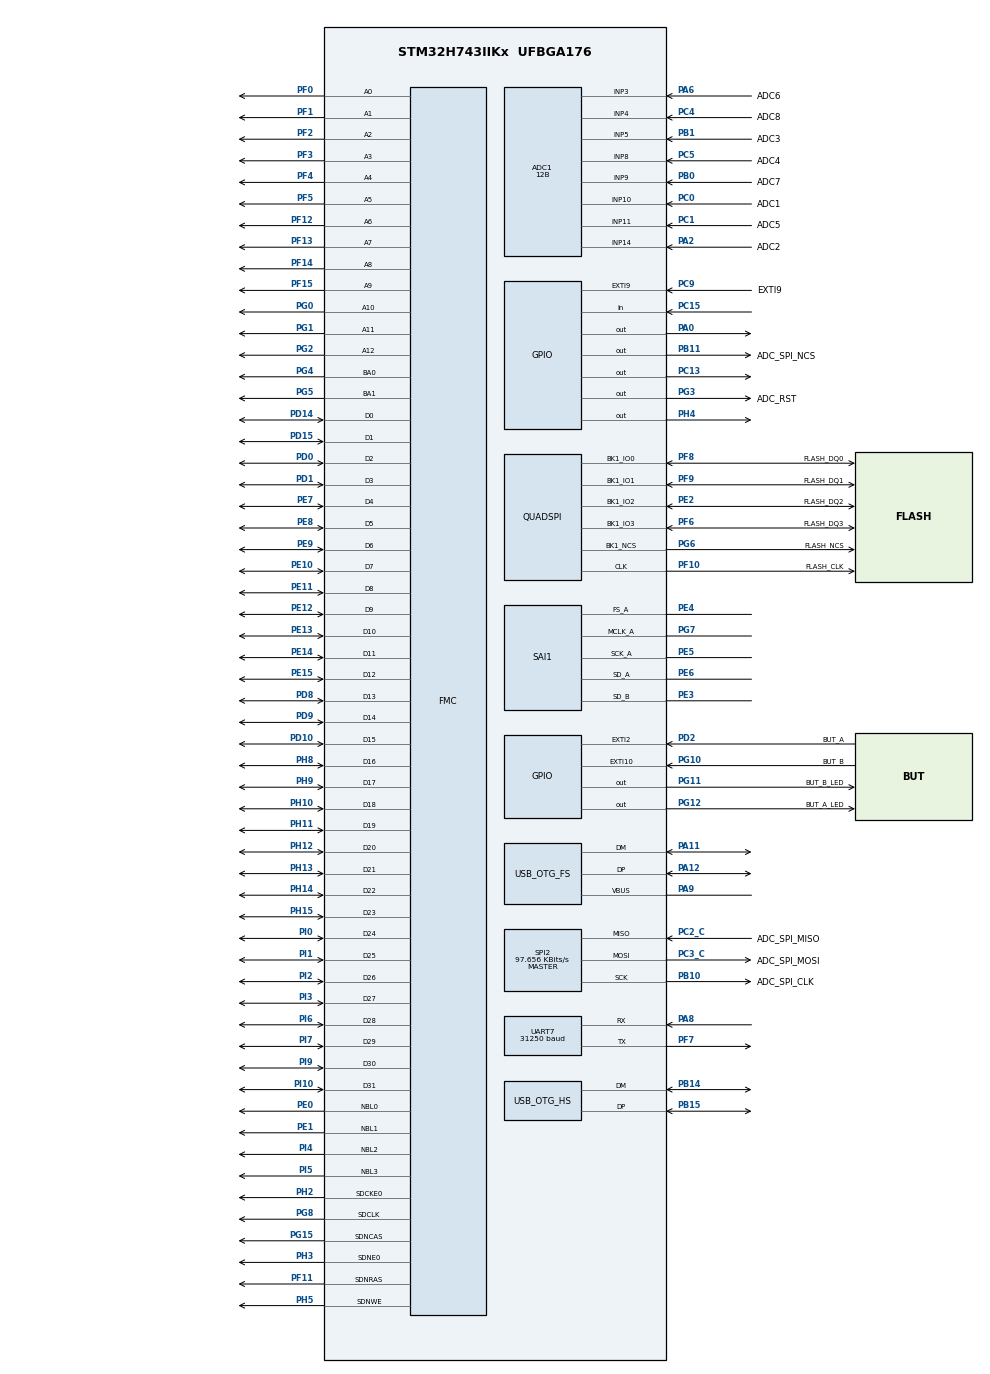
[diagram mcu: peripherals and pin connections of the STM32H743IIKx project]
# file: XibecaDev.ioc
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ADC1.Channel-0\#ChannelRegularConversion=ADC_CHANNEL_10
ADC1.Channel-1\#ChannelRegularConversion=ADC_CHANNEL_11
ADC1.Channel-2\#ChannelRegularConversion=ADC_CHANNEL_14
ADC1.Channel-3\#ChannelRegularConversion=ADC_CHANNEL_3
ADC1.Channel-4\#ChannelRegularConversion=ADC_CHANNEL_5
ADC1.Channel-5\#ChannelRegularConversion=ADC_CHANNEL_9
ADC1.Channel-6\#ChannelRegularConversion=ADC_CHANNEL_8
ADC1.Channel-7\#ChannelRegularConversion=ADC_CHANNEL_4
ADC1.ClockPrescaler=ADC_CLOCK_ASYNC_DIV128
ADC1.ContinuousConvMode=ENABLE
ADC1.ConversionDataManagement=ADC_CONVERSIONDATA_DMA_CIRCULAR
ADC1.EOCSelection=ADC_EOC_SEQ_CONV
ADC1.NbrOfConversion=8
ADC1.NbrOfConversionFlag=1
ADC1.OffsetNumber-0\#ChannelRegularConversion=ADC_OFFSET_NONE
ADC1.OffsetNumber-1\#ChannelRegularConversion=ADC_OFFSET_NONE
ADC1.OffsetNumber-2\#ChannelRegularConversion=ADC_OFFSET_NONE
ADC1.OffsetNumber-3\#ChannelRegularConversion=ADC_OFFSET_NONE
ADC1.OffsetNumber-4\#ChannelRegularConversion=ADC_OFFSET_NONE
ADC1.OffsetNumber-5\#ChannelRegularConversion=ADC_OFFSET_NONE
ADC1.OffsetNumber-6\#ChannelRegularConversion=ADC_OFFSET_NONE
ADC1.OffsetNumber-7\#ChannelRegularConversion=ADC_OFFSET_NONE
ADC1.OffsetSignedSaturation-0\#ChannelRegularConversion=DISABLE
ADC1.OffsetSignedSaturation-1\#ChannelRegularConversion=DISABLE
ADC1.OffsetSignedSaturation-2\#ChannelRegularConversion=DISABLE
ADC1.OffsetSignedSaturation-3\#ChannelRegularConversion=DISABLE
ADC1.Overrun=ADC_OVR_DATA_OVERWRITTEN
ADC1.OversamplingMode=DISABLE
ADC1.Rank-0\#ChannelRegularConversion=1
ADC1.Rank-1\#ChannelRegularConversion=2
ADC1.Rank-2\#ChannelRegularConversion=3
ADC1.Rank-3\#ChannelRegularConversion=4
ADC1.Rank-4\#ChannelRegularConversion=5
ADC1.Rank-5\#ChannelRegularConversion=6
ADC1.Rank-6\#ChannelRegularConversion=7
ADC1.Rank-7\#ChannelRegularConversion=8
ADC1.Resolution=ADC_RESOLUTION_12B
ADC1.SamplingTime-0\#ChannelRegularConversion=ADC_SAMPLETIME_64CYCLES_5
ADC1.SamplingTime-1\#ChannelRegularConversion=ADC_SAMPLETIME_64CYCLES_5
ADC1.SamplingTime-2\#ChannelRegularConversion=ADC_SAMPLETIME_64CYCLES_5
ADC1.SamplingTime-3\#ChannelRegularConversion=ADC_SAMPLETIME_64CYCLES_5
ADC1.SamplingTime-4\#ChannelRegularConversion=ADC_SAMPLETIME_64CYCLES_5
ADC1.SamplingTime-5\#ChannelRegularConversion=ADC_SAMPLETIME_64CYCLES_5
ADC1.SamplingTime-6\#ChannelRegularConversion=ADC_SAMPLETIME_64CYCLES_5
ADC1.SamplingTime-7\#ChannelRegularConversion=ADC_SAMPLETIME_64CYCLES_5
ADC1.master=1
Dma.ADC1.2.Direction=DMA_PERIPH_TO_MEMORY
Dma.ADC1.2.EventEnable=DISABLE
Dma.ADC1.2.FIFOMode=DMA_FIFOMODE_DISABLE
Dma.ADC1.2.Instance=DMA1_Stream3
Dma.ADC1.2.MemDataAlignment=DMA_MDATAALIGN_HALFWORD
Dma.ADC1.2.MemInc=DMA_MINC_ENABLE
Dma.ADC1.2.Mode=DMA_CIRCULAR
Dma.ADC1.2.PeriphDataAlignment=DMA_PDATAALIGN_HALFWORD
Dma.ADC1.2.PeriphInc=DMA_PINC_DISABLE
Dma.ADC1.2.Polarity=HAL_DMAMUX_REQ_GEN_RISING
Dma.ADC1.2.Priority=DMA_PRIORITY_LOW
Dma.ADC1.2.RequestNumber=1
Dma.ADC1.2.SignalID=NONE
Dma.ADC1.2.SyncEnable=DISABLE
Dma.ADC1.2.SyncPolarity=HAL_DMAMUX_SYNC_NO_EVENT
Dma.ADC1.2.SyncRequestNumber=1
Dma.ADC1.2.SyncSignalID=NONE
Dma.Request0=SAI1_A
Dma.Request1=SAI1_B
Dma.Request2=ADC1
Dma.Request3=UART7_RX
Dma.Request4=UART7_TX
Dma.SAI1_A.0.Direction=DMA_PERIPH_TO_MEMORY
Dma.SAI1_A.0.EventEnable=DISABLE
Dma.SAI1_A.0.FIFOMode=DMA_FIFOMODE_DISABLE
Dma.SAI1_A.0.Instance=DMA1_Stream0
Dma.SAI1_A.0.MemDataAlignment=DMA_MDATAALIGN_WORD
Dma.SAI1_A.0.MemInc=DMA_MINC_ENABLE
Dma.SAI1_A.0.Mode=DMA_CIRCULAR
Dma.SAI1_A.0.PeriphDataAlignment=DMA_PDATAALIGN_WORD
Dma.SAI1_A.0.PeriphInc=DMA_PINC_DISABLE
Dma.SAI1_A.0.Polarity=HAL_DMAMUX_REQ_GEN_RISING
Dma.SAI1_A.0.Priority=DMA_PRIORITY_VERY_HIGH
Dma.SAI1_A.0.RequestNumber=1
Dma.SAI1_A.0.SignalID=NONE
Dma.SAI1_A.0.SyncEnable=DISABLE
Dma.SAI1_A.0.SyncPolarity=HAL_DMAMUX_SYNC_NO_EVENT
Dma.SAI1_A.0.SyncRequestNumber=1
Dma.SAI1_A.0.SyncSignalID=NONE
Dma.SAI1_B.1.Direction=DMA_MEMORY_TO_PERIPH
Dma.SAI1_B.1.EventEnable=DISABLE
Dma.SAI1_B.1.FIFOMode=DMA_FIFOMODE_DISABLE
Dma.SAI1_B.1.Instance=DMA1_Stream1
Dma.SAI1_B.1.MemDataAlignment=DMA_MDATAALIGN_WORD
Dma.SAI1_B.1.MemInc=DMA_MINC_ENABLE
Dma.SAI1_B.1.Mode=DMA_CIRCULAR
Dma.SAI1_B.1.PeriphDataAlignment=DMA_PDATAALIGN_WORD
Dma.SAI1_B.1.PeriphInc=DMA_PINC_DISABLE
Dma.SAI1_B.1.Polarity=HAL_DMAMUX_REQ_GEN_RISING
Dma.SAI1_B.1.Priority=DMA_PRIORITY_VERY_HIGH
Dma.SAI1_B.1.RequestNumber=1
Dma.SAI1_B.1.SignalID=NONE
Dma.SAI1_B.1.SyncEnable=DISABLE
Dma.SAI1_B.1.SyncPolarity=HAL_DMAMUX_SYNC_NO_EVENT
Dma.SAI1_B.1.SyncRequestNumber=1
Dma.SAI1_B.1.SyncSignalID=NONE
Dma.UART7_RX.3.Direction=DMA_PERIPH_TO_MEMORY
Dma.UART7_RX.3.EventEnable=DISABLE
Dma.UART7_RX.3.FIFOMode=DMA_FIFOMODE_DISABLE
Dma.UART7_RX.3.Instance=DMA1_Stream2
Dma.UART7_RX.3.MemDataAlignment=DMA_MDATAALIGN_BYTE
Dma.UART7_RX.3.MemInc=DMA_MINC_ENABLE
Dma.UART7_RX.3.Mode=DMA_NORMAL
Dma.UART7_RX.3.PeriphDataAlignment=DMA_PDATAALIGN_BYTE
Dma.UART7_RX.3.PeriphInc=DMA_PINC_DISABLE
Dma.UART7_RX.3.Polarity=HAL_DMAMUX_REQ_GEN_RISING
Dma.UART7_RX.3.Priority=DMA_PRIORITY_LOW
Dma.UART7_RX.3.RequestNumber=1
Dma.UART7_RX.3.SignalID=NONE
Dma.UART7_RX.3.SyncEnable=DISABLE
Dma.UART7_RX.3.SyncPolarity=HAL_DMAMUX_SYNC_NO_EVENT
Dma.UART7_RX.3.SyncRequestNumber=1
Dma.UART7_RX.3.SyncSignalID=NONE
Dma.UART7_TX.4.Direction=DMA_MEMORY_TO_PERIPH
Dma.UART7_TX.4.EventEnable=DISABLE
Dma.UART7_TX.4.FIFOMode=DMA_FIFOMODE_DISABLE
Dma.UART7_TX.4.Instance=DMA1_Stream4
Dma.UART7_TX.4.MemDataAlignment=DMA_MDATAALIGN_BYTE
Dma.UART7_TX.4.MemInc=DMA_MINC_ENABLE
Dma.UART7_TX.4.Mode=DMA_NORMAL
Dma.UART7_TX.4.PeriphDataAlignment=DMA_PDATAALIGN_BYTE
Dma.UART7_TX.4.PeriphInc=DMA_PINC_DISABLE
Dma.UART7_TX.4.Polarity=HAL_DMAMUX_REQ_GEN_RISING
Dma.UART7_TX.4.Priority=DMA_PRIORITY_LOW
Dma.UART7_TX.4.RequestNumber=1
Dma.UART7_TX.4.SignalID=NONE
Dma.UART7_TX.4.SyncEnable=DISABLE
Dma.UART7_TX.4.SyncPolarity=HAL_DMAMUX_SYNC_NO_EVENT
Dma.UART7_TX.4.SyncRequestNumber=1
Dma.UART7_TX.4.SyncSignalID=NONE
FMC.CASLatency1=FMC_SDRAM_CAS_LATENCY_3
FMC.ColumnBitsNumber1=FMC_SDRAM_COLUMN_BITS_NUM_9
FMC.ExitSelfRefreshDelay1=7
FMC.LoadToActiveDelay1=2
FMC.RCDDelay1=10
FMC.RPDelay1=1
FMC.RPDelay2=1
FMC.ReadBurst1=FMC_SDRAM_RBURST_ENABLE
FMC.ReadBurst2=FMC_SDRAM_RBURST_ENABLE
FMC.RowCycleDelay1=8
FMC.RowCycleDelay2=8
FMC.SDClockPeriod1=FMC_SDRAM_CLOCK_PERIOD_2
FMC.SDClockPeriod2=FMC_SDRAM_CLOCK_PERIOD_2
FMC.SelfRefreshTime1=4
FMC.WriteRecoveryTime1=3
FREERTOS.INCLUDE_vTaskDelayUntil=1
FREERTOS.Tasks01=defaultTask,0,1024,StartDefaultTask,Default,NULL,Dynamic,NULL,NULL
FREERTOS.configCHECK_FOR_STACK_OVERFLOW=2
FREERTOS.configUSE_IDLE_HOOK=0
FREERTOS.configUSE_MALLOC_FAILED_HOOK=1
FREERTOS.configUSE_MUTEXES=0
FREERTOS.configUSE_PREEMPTION=0
FREERTOS.configUSE_TICK_HOOK=0
Mcu.Family=STM32H7
Mcu.Name=STM32H743IIKx
Mcu.Package=UFBGA176
NVIC.ADC_IRQn=true\:5\:0\:false\:false\:true\:true\:true\:true
NVIC.DMA1_Stream0_IRQn=true\:5\:0\:false\:false\:true\:true\:false\:true
NVIC.DMA1_Stream1_IRQn=true\:5\:0\:false\:false\:true\:true\:false\:true
NVIC.DMA1_Stream2_IRQn=true\:5\:0\:false\:false\:true\:true\:false\:true
NVIC.DMA1_Stream3_IRQn=true\:5\:0\:false\:false\:true\:true\:false\:true
NVIC.DMA1_Stream4_IRQn=true\:5\:0\:false\:false\:true\:true\:false\:true
NVIC.EXTI15_10_IRQn=true\:5\:0\:false\:false\:true\:true\:true\:true
NVIC.EXTI2_IRQn=true\:5\:0\:false\:false\:true\:true\:true\:true
NVIC.OTG_FS_IRQn=true\:5\:0\:false\:false\:true\:true\:true\:true
NVIC.OTG_HS_IRQn=true\:5\:0\:false\:false\:true\:true\:false\:true
NVIC.PriorityGroup=NVIC_PRIORITYGROUP_4
NVIC.QUADSPI_IRQn=true\:5\:0\:false\:false\:true\:true\:true\:true
NVIC.SAI1_IRQn=true\:5\:0\:false\:false\:true\:true\:true\:true
NVIC.UART7_IRQn=true\:5\:0\:false\:false\:true\:true\:true\:true
PA0.Signal=GPIO_Output
PA11.Mode=Device_Only
PA11.Signal=USB_OTG_FS_DM
PA12.Mode=Device_Only
PA12.Signal=USB_OTG_FS_DP
PA13\ (JTMS/SWDIO).Mode=Trace_Asynchronous_SW
PA13\ (JTMS/SWDIO).Signal=DEBUG_JTMS-SWDIO
PA14\ (JTCK/SWCLK).Mode=Trace_Asynchronous_SW
PA14\ (JTCK/SWCLK).Signal=DEBUG_JTCK-SWCLK
PA2.GPIO_Label=ADC2
PA2.Signal=ADCx_INP14
PA6.GPIO_Label=ADC6
PA6.Signal=ADCx_INP3
PA8.Mode=Asynchronous
PA8.Signal=UART7_RX
PA9.Mode=Activate_VBUS
PA9.Signal=USB_OTG_FS_VBUS
PB0.GPIO_Label=ADC7
PB0.Signal=ADCx_INP9
PB1.GPIO_Label=ADC3
PB1.Signal=ADCx_INP5
PB10.GPIO_Label=ADC_SPI_CLK
PB10.GPIO_Speed=GPIO_SPEED_FREQ_VERY_HIGH
PB10.Mode=Full_Duplex_Master
PB10.Signal=SPI2_SCK
PB11.GPIO_Label=ADC_SPI_NCS
PB11.Signal=GPIO_Output
PB14.Mode=Host_FS
PB14.Signal=USB_OTG_HS_DM
PB15.Mode=Host_FS
PB15.Signal=USB_OTG_HS_DP
PB3\ (JTDO/TRACESWO).Mode=Trace_Asynchronous_SW
PB3\ (JTDO/TRACESWO).Signal=DEBUG_JTDO-SWO
PB7.Signal=I2C1_SDA
PC0.GPIO_Label=ADC1
PC0.Signal=ADCx_INP10
PC1.GPIO_Label=ADC5
PC1.Signal=ADCx_INP11
PC10.GPIO_Speed=GPIO_SPEED_FREQ_HIGH
PC10.Signal=SharedStack_PC10
PC10.Stacked=true
PC12.GPIO_Speed=GPIO_SPEED_FREQ_HIGH
PC12.Signal=SharedStack_PC12
PC12.Stacked=true
PC13.Signal=GPIO_Output
PC15-OSC32_OUT\ (OSC32_OUT).Signal=GPIO_Input
PC2_C.GPIO_Label=ADC_SPI_MISO
PC2_C.GPIO_Speed=GPIO_SPEED_FREQ_VERY_HIGH
PC2_C.Mode=Full_Duplex_Master
PC2_C.Signal=SPI2_MISO
PC3_C.GPIO_Label=ADC_SPI_MOSI
PC3_C.GPIO_Speed=GPIO_SPEED_FREQ_VERY_HIGH
PC3_C.Mode=Full_Duplex_Master
PC3_C.Signal=SPI2_MOSI
PC4.GPIO_Label=ADC8
PC4.Signal=ADCx_INP4
PC5.GPIO_Label=ADC4
PC5.Signal=ADCx_INP8
PC9.GPIO_Label=EXTI9
PC9.Signal=SharedStack_PC9
PC9.Stacked=true
PD0.Signal=FMC_D2_DA2
PD1.Signal=FMC_D3_DA3
PD10.Signal=FMC_D15_DA15
PD14.Signal=FMC_D0_DA0
PD15.Signal=FMC_D1_DA1
PD2.GPIO_Label=BUT_A
PD2.GPIO_PuPd=GPIO_PULLUP
PD2.Signal=GPXTI2
PD8.Signal=FMC_D13_DA13
PD9.Signal=FMC_D14_DA14
PE0.Signal=FMC_NBL0
PE1.Signal=FMC_NBL1
PE10.Signal=FMC_D7_DA7
PE11.Signal=FMC_D8_DA8
PE12.Signal=FMC_D9_DA9
PE13.Signal=FMC_D10_DA10
PE14.Signal=FMC_D11_DA11
PE15.Signal=FMC_D12_DA12
PE2.GPIO_Label=FLASH_DQ2
PE2.GPIO_Speed=GPIO_SPEED_FREQ_VERY_HIGH
PE2.Mode=Single Bank 1
PE2.Signal=QUADSPI_BK1_IO2
PE3.GPIO_Speed=GPIO_SPEED_FREQ_VERY_HIGH
PE3.Mode=SAI_B_SyncSlave
PE3.Signal=SAI1_SD_B
PE4.GPIO_Speed=GPIO_SPEED_FREQ_VERY_HIGH
PE4.Mode=SAI_A_MasterWithClock
PE4.Signal=SAI1_FS_A
PE5.GPIO_Speed=GPIO_SPEED_FREQ_VERY_HIGH
PE5.Mode=SAI_A_MasterWithClock
PE5.Signal=SAI1_SCK_A
PE6.GPIO_Speed=GPIO_SPEED_FREQ_VERY_HIGH
PE6.Mode=SAI_A_MasterWithClock
PE6.Signal=SAI1_SD_A
PE7.Signal=FMC_D4_DA4
PE8.Signal=FMC_D5_DA5
PE9.Signal=FMC_D6_DA6
PF0.Signal=FMC_A0
PF1.Signal=FMC_A1
PF10.GPIO_Label=FLASH_CLK
PF10.GPIO_Speed=GPIO_SPEED_FREQ_VERY_HIGH
PF10.Mode=Single Bank 1
PF10.Signal=QUADSPI_CLK
PF11.Signal=FMC_SDNRAS
PF12.Signal=FMC_A6
PF13.Signal=FMC_A7
PF14.Signal=FMC_A8
PF15.Signal=FMC_A9
PF2.Signal=FMC_A2
PF3.Signal=FMC_A3
PF4.Signal=FMC_A4
PF5.Signal=FMC_A5
PF6.GPIO_Label=FLASH_DQ3
PF6.GPIO_Speed=GPIO_SPEED_FREQ_VERY_HIGH
PF6.Mode=Single Bank 1
PF6.Signal=QUADSPI_BK1_IO3
PF7.Mode=Asynchronous
PF7.Signal=UART7_TX
PF8.GPIO_Label=FLASH_DQ0
PF8.GPIO_Speed=GPIO_SPEED_FREQ_VERY_HIGH
PF8.Mode=Single Bank 1
PF8.Signal=QUADSPI_BK1_IO0
PF9.GPIO_Label=FLASH_DQ1
PF9.GPIO_Speed=GPIO_SPEED_FREQ_VERY_HIGH
PF9.Mode=Single Bank 1
PF9.Signal=QUADSPI_BK1_IO1
PG0.Signal=FMC_A10
PG1.Signal=FMC_A11
PG10.GPIO_Label=BUT_B
PG10.GPIO_PuPd=GPIO_PULLUP
PG10.Signal=GPXTI10
PG11.GPIO_Label=BUT_B_LED
PG11.Signal=GPIO_Output
PG12.GPIO_Label=BUT_A_LED
PG12.Signal=GPIO_Output
PG15.Signal=FMC_SDNCAS
PG2.Signal=FMC_A12
PG3.GPIO_Label=ADC_RST
PG3.Signal=GPIO_Output
PG4.Signal=FMC_A14_BA0
PG5.Signal=FMC_A15_BA1
PG6.GPIO_Label=FLASH_NCS
PG6.GPIO_Speed=GPIO_SPEED_FREQ_VERY_HIGH
PG6.Mode=Single Bank 1
PG6.Signal=QUADSPI_BK1_NCS
PG7.GPIO_Speed=GPIO_SPEED_FREQ_VERY_HIGH
PG7.Mode=SAI_A_MasterWithClock
PG7.Signal=SAI1_MCLK_A
PG8.Signal=FMC_SDCLK
PH0-OSC_IN\ (PH0).Mode=HSE-External-Oscillator
PH0-OSC_IN\ (PH0).Signal=RCC_OSC_IN
PH1-OSC_OUT\ (PH1).Mode=HSE-External-Oscillator
PH1-OSC_OUT\ (PH1).Signal=RCC_OSC_OUT
PH10.Signal=FMC_D18
PH11.Signal=FMC_D19
PH12.Signal=FMC_D20
PH13.Signal=FMC_D21
PH14.Signal=FMC_D22
PH15.Signal=FMC_D23
PH2.Mode=SdramChipSelect1_1
PH2.Signal=FMC_SDCKE0
PH3.Mode=SdramChipSelect1_1
PH3.Signal=FMC_SDNE0
PH4.Signal=GPIO_Output
PH5.Signal=FMC_SDNWE
PH8.Signal=FMC_D16
PH9.Signal=FMC_D17
PI0.Signal=FMC_D24
PI1.Signal=FMC_D25
PI10.Signal=FMC_D31
PI2.Signal=FMC_D26
PI3.Signal=FMC_D27
PI4.Signal=FMC_NBL2
PI5.Signal=FMC_NBL3
PI6.Signal=FMC_D28
PI7.Signal=FMC_D29
PI9.Signal=FMC_D30
ProjectManager.HeapSize=0x200
ProjectManager.StackSize=0x400
ProjectManager.TargetToolchain=Other Toolchains (GPDSC)
QUADSPI.ClockPrescaler=9
QUADSPI.FifoThreshold=4
QUADSPI.FlashSize=22
RCC.ADCFreq_Value=25000000
RCC.APB1Freq_Value=120000000
RCC.APB2Freq_Value=120000000
RCC.APB3Freq_Value=120000000
RCC.APB4Freq_Value=120000000
RCC.CortexFreq_Value=480000000
RCC.D1PPRE=RCC_APB3_DIV2
RCC.D2PPRE1=RCC_APB1_DIV2
RCC.D2PPRE2=RCC_APB2_DIV2
RCC.D3PPRE=RCC_APB4_DIV2
RCC.DIVM1=1
RCC.DIVM2=1
RCC.DIVM3=7
RCC.DIVN1=120
RCC.DIVN2=18
RCC.DIVN3=172
RCC.DIVP2=6
RCC.DIVQ1=5
RCC.HCLKFreq_Value=240000000
RCC.HPRE=RCC_HCLK_DIV2
RCC.HSE_VALUE=8000000
RCC.PLL2FRACN=6144
RCC.PLL3FRACN=0
RCC.PLLFRACN=0
RCC.PLLSourceVirtual=RCC_PLLSOURCE_HSE
RCC.PWR_Regulator_Voltage_Scale=PWR_REGULATOR_VOLTAGE_SCALE0
RCC.SAI1CLockSelection=RCC_SAI1CLKSOURCE_PLL3
RCC.SPI123CLockSelection=RCC_SPI123CLKSOURCE_PLL2
RCC.SYSCLKFreq_VALUE=480000000
RCC.SYSCLKSource=RCC_SYSCLKSOURCE_PLLCLK
RCC.USBCLockSelection=RCC_USBCLKSOURCE_HSI48
RCC.USBFreq_Value=48000000
SAI1.ActiveFrameLength-SAI_A_MasterWithClock=128
SAI1.ActiveFrameLength-SAI_B_SyncSlave=128
SAI1.AudioFrequency-SAI_A_MasterWithClock=SAI_AUDIO_FREQUENCY_48K
SAI1.AudioMode-SAI_A_MasterWithClock=SAI_MODEMASTER_RX
SAI1.AudioMode-SAI_B_SyncSlave=SAI_MODESLAVE_TX
SAI1.ClockStrobing-SAI_A_MasterWithClock=SAI_CLOCKSTROBING_RISINGEDGE
SAI1.DataSize-SAI_A_MasterWithClock=SAI_DATASIZE_24
SAI1.DataSize-SAI_B_SyncSlave=SAI_DATASIZE_24
SAI1.ErrorAudioFreq-SAI_A_MasterWithClock=-0.01 %
SAI1.FSDefinition-SAI_A_MasterWithClock=SAI_FS_CHANNEL_IDENTIFICATION
SAI1.FSDefinition-SAI_B_SyncSlave=SAI_FS_CHANNEL_IDENTIFICATION
SAI1.FSOffset-SAI_A_MasterWithClock=SAI_FS_BEFOREFIRSTBIT
SAI1.FSOffset-SAI_B_SyncSlave=SAI_FS_BEFOREFIRSTBIT
SAI1.FSPolarity-SAI_A_MasterWithClock=SAI_FS_ACTIVE_HIGH
SAI1.FSPolarity-SAI_B_SyncSlave=SAI_FS_ACTIVE_HIGH
SAI1.FrameLength-SAI_A_MasterWithClock=256
SAI1.FrameLength-SAI_B_SyncSlave=256
SAI1.Instance-SAI_A_MasterWithClock=SAI$Index_Block_A
SAI1.Instance-SAI_B_SyncSlave=SAI$Index_Block_B
SAI1.MClockEnable-SAI_A_MasterWithClock=SAI_MASTERCLOCK_ENABLE
SAI1.NoDivider-SAI_A_MasterWithClock=SAI_MASTERDIVIDER_ENABLE
SAI1.OutputDrive-SAI_A_MasterWithClock=SAI_OUTPUTDRIVE_ENABLE
SAI1.OutputDrive-SAI_B_SyncSlave=SAI_OUTPUTDRIVE_ENABLE
SAI1.RealAudioFreq-SAI_A_MasterWithClock=47.991 KHz
SAI1.SlotActive-SAI_A_MasterWithClock=0x0000FFFF
SAI1.SlotActive-SAI_B_SyncSlave=0x0000FFFF
SAI1.SlotNumber-SAI_A_MasterWithClock=8
SAI1.SlotNumber-SAI_B_SyncSlave=8
SAI1.SlotSize-SAI_A_MasterWithClock=SAI_SLOTSIZE_32B
SAI1.SlotSize-SAI_B_SyncSlave=SAI_SLOTSIZE_32B
SAI1.VirtualMode-SAI_A_MasterWithClock=VM_MASTER
SAI1.VirtualMode-SAI_B_SyncSlave=VM_SLAVE
SAI1.VirtualSlotActive-SAI_A_MasterWithClock=SAI_SLOTACTIVE_ALL
SAI1.VirtualSlotActive-SAI_B_SyncSlave=SAI_SLOTACTIVE_ALL
SH.ADCx_INP10.0=ADC1_INP10,IN10-Single-Ended
SH.ADCx_INP11.0=ADC1_INP11,IN11-Single-Ended
SH.ADCx_INP14.0=ADC1_INP14,IN14-Single-Ended
SH.ADCx_INP3.0=ADC1_INP3,IN3-Single-Ended
SH.ADCx_INP4.0=ADC1_INP4,IN4-Single-Ended
SH.ADCx_INP5.0=ADC1_INP5,IN5-Single-Ended
SH.ADCx_INP8.0=ADC1_INP8,IN8-Single-Ended
SH.ADCx_INP9.0=ADC1_INP9,IN9-Single-Ended
SH.FMC_A0.0=FMC_A0,13b-sda1
SH.FMC_A1.0=FMC_A1,13b-sda1
SH.FMC_A10.0=FMC_A10,13b-sda1
SH.FMC_A11.0=FMC_A11,13b-sda1
SH.FMC_A12.0=FMC_A12,13b-sda1
SH.FMC_A14_BA0.0=FMC_BA0,FourSdramBanks1
SH.FMC_A15_BA1.0=FMC_BA1,FourSdramBanks1
SH.FMC_A2.0=FMC_A2,13b-sda1
SH.FMC_A3.0=FMC_A3,13b-sda1
SH.FMC_A4.0=FMC_A4,13b-sda1
SH.FMC_A5.0=FMC_A5,13b-sda1
SH.FMC_A6.0=FMC_A6,13b-sda1
SH.FMC_A7.0=FMC_A7,13b-sda1
SH.FMC_A8.0=FMC_A8,13b-sda1
SH.FMC_A9.0=FMC_A9,13b-sda1
SH.FMC_D0_DA0.0=FMC_D0,sd-32b-d1
SH.FMC_D10_DA10.0=FMC_D10,sd-32b-d1
SH.FMC_D11_DA11.0=FMC_D11,sd-32b-d1
SH.FMC_D12_DA12.0=FMC_D12,sd-32b-d1
SH.FMC_D13_DA13.0=FMC_D13,sd-32b-d1
SH.FMC_D14_DA14.0=FMC_D14,sd-32b-d1
SH.FMC_D15_DA15.0=FMC_D15,sd-32b-d1
SH.FMC_D16.0=FMC_D16,sd-32b-d1
SH.FMC_D17.0=FMC_D17,sd-32b-d1
SH.FMC_D18.0=FMC_D18,sd-32b-d1
SH.FMC_D19.0=FMC_D19,sd-32b-d1
SH.FMC_D1_DA1.0=FMC_D1,sd-32b-d1
SH.FMC_D20.0=FMC_D20,sd-32b-d1
SH.FMC_D21.0=FMC_D21,sd-32b-d1
SH.FMC_D22.0=FMC_D22,sd-32b-d1
SH.FMC_D23.0=FMC_D23,sd-32b-d1
SH.FMC_D24.0=FMC_D24,sd-32b-d1
SH.FMC_D25.0=FMC_D25,sd-32b-d1
SH.FMC_D26.0=FMC_D26,sd-32b-d1
SH.FMC_D27.0=FMC_D27,sd-32b-d1
SH.FMC_D28.0=FMC_D28,sd-32b-d1
SH.FMC_D29.0=FMC_D29,sd-32b-d1
SH.FMC_D2_DA2.0=FMC_D2,sd-32b-d1
SH.FMC_D30.0=FMC_D30,sd-32b-d1
SH.FMC_D31.0=FMC_D31,sd-32b-d1
SH.FMC_D3_DA3.0=FMC_D3,sd-32b-d1
SH.FMC_D4_DA4.0=FMC_D4,sd-32b-d1
SH.FMC_D5_DA5.0=FMC_D5,sd-32b-d1
SH.FMC_D6_DA6.0=FMC_D6,sd-32b-d1
SH.FMC_D7_DA7.0=FMC_D7,sd-32b-d1
SH.FMC_D8_DA8.0=FMC_D8,sd-32b-d1
SH.FMC_D9_DA9.0=FMC_D9,sd-32b-d1
SH.FMC_NBL0.0=FMC_NBL0,Sd4ByteEnable1
SH.FMC_NBL1.0=FMC_NBL1,Sd4ByteEnable1
SH.FMC_NBL2.0=FMC_NBL2,Sd4ByteEnable1
SH.FMC_NBL3.0=FMC_NBL3,Sd4ByteEnable1
SH.FMC_SDCLK.0=FMC_SDCLK,13b-sda1
SH.FMC_SDNCAS.0=FMC_SDNCAS,13b-sda1
SH.FMC_SDNRAS.0=FMC_SDNRAS,13b-sda1
SH.FMC_SDNWE.0=FMC_SDNWE,13b-sda1
SH.SharedStack_PC10.0=SDMMC1_D2
SH.SharedStack_PC10.1=SPI3_SCK
SH.SharedStack_PC12.0=SDMMC1_CK
SH.SharedStack_PC12.1=SPI3_MOSI
SH.SharedStack_PC9.0=SDMMC1_D1
SH.SharedStack_PC9.1=TIM3_CH4
SH.SharedStack_PC9.2=TIM8_CH4
SH.SharedStack_PC9.3=GPIO_EXTI9
SPI2.BaudRatePrescaler=SPI_BAUDRATEPRESCALER_256
SPI2.CLKPhase=SPI_PHASE_2EDGE
SPI2.CLKPolarity=SPI_POLARITY_HIGH
SPI2.CalculateBaudRate=97.656 KBits/s
SPI2.DataSize=SPI_DATASIZE_8BIT
SPI2.Direction=SPI_DIRECTION_2LINES
SPI2.Mode=SPI_MODE_MASTER
SPI2.NSSPMode=SPI_NSS_PULSE_DISABLE
SPI2.VirtualType=VM_MASTER
UART7.BaudRate=31250
USB_DEVICE.CLASS_NAME_FS=AUDIO
USB_DEVICE.MANUFACTURER_STRING-AUDIO_FS=Rebel Technology
USB_DEVICE.PID_AUDIO_FS=0xDADA
USB_DEVICE.PRODUCT_STRING_AUDIO_FS=OWL-ACDC
USB_DEVICE.VID-AUDIO_FS=0x1209
USB_DEVICE.VirtualMode-AUDIO_FS=Audio
USB_DEVICE.VirtualModeFS=Audio_FS
USB_HOST.USBH_HandleTypeDef-AUDIO_HS=hUsbHostHS
USB_HOST.USBH_MAX_NUM_CONFIGURATION-AUDIO_HS=5
USB_HOST.USBH_MAX_NUM_SUPPORTED_CLASS-AUDIO_HS=2
USB_HOST.VirtualModeHS=Audio
USB_OTG_FS.VirtualMode=Device_Only
USB_OTG_HS.VirtualMode-Host_FS=Host_FS
VP_FREERTOS_VS_CMSIS_V1.Mode=CMSIS_V1
VP_USB_DEVICE_VS_USB_DEVICE_AUDIO_FS.Mode=AUDIO_FS
VP_USB_HOST_VS_USB_HOST_AUDIO_HS.Mode=AUDIO_HS
board=custom

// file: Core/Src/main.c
/* USER CODE BEGIN Header */
/**
  ******************************************************************************
  * @file           : main.c
  * @brief          : Main program body
  ******************************************************************************
  * @attention
  *
  * <h2><center>&copy; Copyright (c) 2021 STMicroelectronics.
  * All rights reserved.</center></h2>
  *
  * This software component is licensed by ST under Ultimate Liberty license
  * SLA0044, the "License"; You may not use this file except in compliance with
  * the License. You may obtain a copy of the License at:
  *                             www.st.com/SLA0044
  *
  ******************************************************************************
  */
/* USER CODE END Header */
#include "main.h"
#include "cmsis_os.h"
#include "usb_device.h"
#include "usb_host.h"
#include "usb_device.h"
#include "usb_host.h"

/* USER CODE BEGIN Includes */
#include "device.h"
#include "errorhandlers.h"
/* USER CODE END Includes */

ADC_HandleTypeDef hadc1;
DMA_HandleTypeDef hdma_adc1;

QSPI_HandleTypeDef hqspi;

SAI_HandleTypeDef hsai_BlockA1;
SAI_HandleTypeDef hsai_BlockB1;
DMA_HandleTypeDef hdma_sai1_a;
DMA_HandleTypeDef hdma_sai1_b;

SPI_HandleTypeDef hspi2;

UART_HandleTypeDef huart7;
DMA_HandleTypeDef hdma_uart7_rx;
DMA_HandleTypeDef hdma_uart7_tx;

SDRAM_HandleTypeDef hsdram1;

osThreadId defaultTaskHandle;

void SystemClock_Config(void);
void PeriphCommonClock_Config(void);
static void MX_GPIO_Init(void);
static void MX_DMA_Init(void);
static void MX_QUADSPI_Init(void);
static void MX_FMC_Init(void);
static void MX_SAI1_Init(void);
static void MX_ADC1_Init(void);
static void MX_SPI2_Init(void);
static void MX_UART7_Init(void);
void StartDefaultTask(void const * argument);

/* USER CODE BEGIN PFP */
void setup(void);
void loop(void);
void SDRAM_Initialization_Sequence(SDRAM_HandleTypeDef *hsdram);
void initialise_monitor_handles(void);
/* USER CODE END PFP */

int main(void)
{
  /* USER CODE BEGIN 1 */
#ifdef DEBUG
#warning "DEBUG uses printf and semihosting!"
  if(CoreDebug->DHCSR & 0x01)
    initialise_monitor_handles(); // remove when not semi-hosting
  printf("showtime\n");
#endif
#ifdef USE_ICACHE
  /* Enable I-Cache-------------------------------------------------------------*/
  /* After reset, you must invalidate each cache before enabling (SCB_EnableICache) it. */
  SCB_InvalidateICache();
  SCB_EnableICache();
#endif
#ifdef USE_DCACHE
  /* Enable D-Cache-------------------------------------------------------------*/
  /* Before enabling the data cache, you must invalidate the entire data cache (SCB_InvalidateDCache), because external memory might have changed from when the cache was disabled. */
  SCB_InvalidateDCache();
  SCB_EnableDCache();
#endif

  /* Enable D2 domain SRAM Clocks */
  /* presumably done in SystemInit by setting DATA_IN_D2_SRAM ? */
  /* should be started before libc_init_array and LoopCopyData in startup.s */
  /* __HAL_RCC_D2SRAM1_CLK_ENABLE(); */
  /* __HAL_RCC_D2SRAM2_CLK_ENABLE(); */
  /* __HAL_RCC_D2SRAM3_CLK_ENABLE(); */

  /* USER CODE END 1 */

  /* MCU Configuration--------------------------------------------------------*/

  /* Reset of all peripherals, Initializes the Flash interface and the Systick. */
  HAL_Init();

  /* Configure the system clock */
  SystemClock_Config();

/* Configure the peripherals common clocks */
  PeriphCommonClock_Config();

  /* Initialize all configured peripherals */
  MX_GPIO_Init();
  MX_DMA_Init();
  MX_QUADSPI_Init();
  MX_FMC_Init();
  MX_SAI1_Init();
  MX_ADC1_Init();
  MX_SPI2_Init();
  MX_UART7_Init();
  /* USER CODE BEGIN 2 */

#ifdef USE_EXTERNAL_RAM
  SDRAM_Initialization_Sequence(&hsdram1);
#endif

  /* USER CODE END 2 */

  /* Create the thread(s) */
  /* definition and creation of defaultTask */
  osThreadDef(defaultTask, StartDefaultTask, osPriorityNormal, 0, 1024);
  defaultTaskHandle = osThreadCreate(osThread(defaultTask), NULL);

  /* Start scheduler */
  osKernelStart();

  /* We should never get here as control is now taken by the scheduler */
  /* Infinite loop */
  while (1)
  {

  }
}

void SystemClock_Config(void)
{
  RCC_OscInitTypeDef RCC_OscInitStruct = {0};
  RCC_ClkInitTypeDef RCC_ClkInitStruct = {0};

  /** Supply configuration update enable
  */
  HAL_PWREx_ConfigSupply(PWR_LDO_SUPPLY);
  /** Configure the main internal regulator output voltage
  */
  __HAL_PWR_VOLTAGESCALING_CONFIG(PWR_REGULATOR_VOLTAGE_SCALE0);

  while(!__HAL_PWR_GET_FLAG(PWR_FLAG_VOSRDY)) {}
  /** Macro to configure the PLL clock source
  */
  __HAL_RCC_PLL_PLLSOURCE_CONFIG(RCC_PLLSOURCE_HSE);
  /** Initializes the RCC Oscillators according to the specified parameters
  * in the RCC_OscInitTypeDef structure.
  */
  RCC_OscInitStruct.OscillatorType = RCC_OSCILLATORTYPE_HSI48|RCC_OSCILLATORTYPE_HSE;
  RCC_OscInitStruct.HSEState = RCC_HSE_ON;
  RCC_OscInitStruct.HSI48State = RCC_HSI48_ON;
  RCC_OscInitStruct.PLL.PLLState = RCC_PLL_ON;
  RCC_OscInitStruct.PLL.PLLSource = RCC_PLLSOURCE_HSE;
  RCC_OscInitStruct.PLL.PLLM = 1;
  RCC_OscInitStruct.PLL.PLLN = 120;
  RCC_OscInitStruct.PLL.PLLP = 2;
  RCC_OscInitStruct.PLL.PLLQ = 5;
  RCC_OscInitStruct.PLL.PLLR = 2;
  RCC_OscInitStruct.PLL.PLLRGE = RCC_PLL1VCIRANGE_3;
  RCC_OscInitStruct.PLL.PLLVCOSEL = RCC_PLL1VCOWIDE;
  RCC_OscInitStruct.PLL.PLLFRACN = 0;
  if (HAL_RCC_OscConfig(&RCC_OscInitStruct) != HAL_OK)
  {
    Error_Handler();
  }
  /** Initializes the CPU, AHB and APB buses clocks
  */
  RCC_ClkInitStruct.ClockType = RCC_CLOCKTYPE_HCLK|RCC_CLOCKTYPE_SYSCLK
                              |RCC_CLOCKTYPE_PCLK1|RCC_CLOCKTYPE_PCLK2
                              |RCC_CLOCKTYPE_D3PCLK1|RCC_CLOCKTYPE_D1PCLK1;
  RCC_ClkInitStruct.SYSCLKSource = RCC_SYSCLKSOURCE_PLLCLK;
  RCC_ClkInitStruct.SYSCLKDivider = RCC_SYSCLK_DIV1;
  RCC_ClkInitStruct.AHBCLKDivider = RCC_HCLK_DIV2;
  RCC_ClkInitStruct.APB3CLKDivider = RCC_APB3_DIV2;
  RCC_ClkInitStruct.APB1CLKDivider = RCC_APB1_DIV2;
  RCC_ClkInitStruct.APB2CLKDivider = RCC_APB2_DIV2;
  RCC_ClkInitStruct.APB4CLKDivider = RCC_APB4_DIV2;

  if (HAL_RCC_ClockConfig(&RCC_ClkInitStruct, FLASH_LATENCY_4) != HAL_OK)
  {
    Error_Handler();
  }
}

void PeriphCommonClock_Config(void)
{
  RCC_PeriphCLKInitTypeDef PeriphClkInitStruct = {0};

  /** Initializes the peripherals clock
  */
  PeriphClkInitStruct.PeriphClockSelection = RCC_PERIPHCLK_ADC|RCC_PERIPHCLK_SAI1
                              |RCC_PERIPHCLK_SPI2;
  PeriphClkInitStruct.PLL2.PLL2M = 1;
  PeriphClkInitStruct.PLL2.PLL2N = 18;
  PeriphClkInitStruct.PLL2.PLL2P = 6;
  PeriphClkInitStruct.PLL2.PLL2Q = 2;
  PeriphClkInitStruct.PLL2.PLL2R = 2;
  PeriphClkInitStruct.PLL2.PLL2RGE = RCC_PLL2VCIRANGE_3;
  PeriphClkInitStruct.PLL2.PLL2VCOSEL = RCC_PLL2VCOMEDIUM;
  PeriphClkInitStruct.PLL2.PLL2FRACN = 6144;
  PeriphClkInitStruct.PLL3.PLL3M = 7;
  PeriphClkInitStruct.PLL3.PLL3N = 172;
  PeriphClkInitStruct.PLL3.PLL3P = 2;
  PeriphClkInitStruct.PLL3.PLL3Q = 2;
  PeriphClkInitStruct.PLL3.PLL3R = 2;
  PeriphClkInitStruct.PLL3.PLL3RGE = RCC_PLL3VCIRANGE_0;
  PeriphClkInitStruct.PLL3.PLL3VCOSEL = RCC_PLL3VCOWIDE;
  PeriphClkInitStruct.PLL3.PLL3FRACN = 0;
  PeriphClkInitStruct.Sai1ClockSelection = RCC_SAI1CLKSOURCE_PLL3;
  PeriphClkInitStruct.Spi123ClockSelection = RCC_SPI123CLKSOURCE_PLL2;
  PeriphClkInitStruct.AdcClockSelection = RCC_ADCCLKSOURCE_PLL2;
  if (HAL_RCCEx_PeriphCLKConfig(&PeriphClkInitStruct) != HAL_OK)
  {
    Error_Handler();
  }
}

static void MX_ADC1_Init(void)
{

  ADC_MultiModeTypeDef multimode = {0};
  ADC_ChannelConfTypeDef sConfig = {0};

  /** Common config
  */
  hadc1.Instance = ADC1;
  hadc1.Init.ClockPrescaler = ADC_CLOCK_ASYNC_DIV128;
  hadc1.Init.Resolution = ADC_RESOLUTION_12B;
  hadc1.Init.ScanConvMode = ADC_SCAN_ENABLE;
  hadc1.Init.EOCSelection = ADC_EOC_SEQ_CONV;
  hadc1.Init.LowPowerAutoWait = DISABLE;
  hadc1.Init.ContinuousConvMode = ENABLE;
  hadc1.Init.NbrOfConversion = 8;
  hadc1.Init.DiscontinuousConvMode = DISABLE;
  hadc1.Init.ExternalTrigConv = ADC_SOFTWARE_START;
  hadc1.Init.ExternalTrigConvEdge = ADC_EXTERNALTRIGCONVEDGE_NONE;
  hadc1.Init.ConversionDataManagement = ADC_CONVERSIONDATA_DMA_CIRCULAR;
  hadc1.Init.Overrun = ADC_OVR_DATA_OVERWRITTEN;
  hadc1.Init.LeftBitShift = ADC_LEFTBITSHIFT_NONE;
  hadc1.Init.OversamplingMode = DISABLE;
  if (HAL_ADC_Init(&hadc1) != HAL_OK)
  {
    Error_Handler();
  }
  /** Configure the ADC multi-mode
  */
  multimode.Mode = ADC_MODE_INDEPENDENT;
  if (HAL_ADCEx_MultiModeConfigChannel(&hadc1, &multimode) != HAL_OK)
  {
    Error_Handler();
  }
  /** Configure Regular Channel
  */
  sConfig.Channel = ADC_CHANNEL_10;
  sConfig.Rank = ADC_REGULAR_RANK_1;
  sConfig.SamplingTime = ADC_SAMPLETIME_64CYCLES_5;
  sConfig.SingleDiff = ADC_SINGLE_ENDED;
  sConfig.OffsetNumber = ADC_OFFSET_NONE;
  sConfig.Offset = 0;
  sConfig.OffsetSignedSaturation = DISABLE;
  if (HAL_ADC_ConfigChannel(&hadc1, &sConfig) != HAL_OK)
  {
    Error_Handler();
  }
  /** Configure Regular Channel
  */
  sConfig.Channel = ADC_CHANNEL_11;
  sConfig.Rank = ADC_REGULAR_RANK_2;
  if (HAL_ADC_ConfigChannel(&hadc1, &sConfig) != HAL_OK)
  {
    Error_Handler();
  }
  /** Configure Regular Channel
  */
  sConfig.Channel = ADC_CHANNEL_14;
  sConfig.Rank = ADC_REGULAR_RANK_3;
  if (HAL_ADC_ConfigChannel(&hadc1, &sConfig) != HAL_OK)
  {
    Error_Handler();
  }
  /** Configure Regular Channel
  */
  sConfig.Channel = ADC_CHANNEL_3;
  sConfig.Rank = ADC_REGULAR_RANK_4;
  if (HAL_ADC_ConfigChannel(&hadc1, &sConfig) != HAL_OK)
  {
    Error_Handler();
  }
  /** Configure Regular Channel
  */
  sConfig.Channel = ADC_CHANNEL_5;
  sConfig.Rank = ADC_REGULAR_RANK_5;
  if (HAL_ADC_ConfigChannel(&hadc1, &sConfig) != HAL_OK)
  {
    Error_Handler();
  }
  /** Configure Regular Channel
  */
  sConfig.Channel = ADC_CHANNEL_9;
  sConfig.Rank = ADC_REGULAR_RANK_6;
  if (HAL_ADC_ConfigChannel(&hadc1, &sConfig) != HAL_OK)
  {
    Error_Handler();
  }
  /** Configure Regular Channel
  */
  sConfig.Channel = ADC_CHANNEL_8;
  sConfig.Rank = ADC_REGULAR_RANK_7;
  if (HAL_ADC_ConfigChannel(&hadc1, &sConfig) != HAL_OK)
  {
    Error_Handler();
  }
  /** Configure Regular Channel
  */
  sConfig.Channel = ADC_CHANNEL_4;
  sConfig.Rank = ADC_REGULAR_RANK_8;
  if (HAL_ADC_ConfigChannel(&hadc1, &sConfig) != HAL_OK)
  {
    Error_Handler();
  }

}

static void MX_QUADSPI_Init(void)
{

  /* QUADSPI parameter configuration*/
  hqspi.Instance = QUADSPI;
  hqspi.Init.ClockPrescaler = 9;
  hqspi.Init.FifoThreshold = 4;
  hqspi.Init.SampleShifting = QSPI_SAMPLE_SHIFTING_NONE;
  hqspi.Init.FlashSize = POSITION_VAL(EXTERNAL_STORAGE_SIZE) - 1;
  hqspi.Init.ChipSelectHighTime = QSPI_CS_HIGH_TIME_1_CYCLE;
  hqspi.Init.ClockMode = QSPI_CLOCK_MODE_0;
  hqspi.Init.FlashID = QSPI_FLASH_ID_1;
  hqspi.Init.DualFlash = QSPI_DUALFLASH_DISABLE;
  if (HAL_QSPI_Init(&hqspi) != HAL_OK)
  {
    Error_Handler();
  }
  /* USER CODE BEGIN QUADSPI_Init 2 */
  if( HAL_QSPI_SetFifoThreshold(&hqspi, 16) != HAL_OK)
    {
      Error_Handler();
    }
  /* USER CODE END QUADSPI_Init 2 */

}

static void MX_SAI1_Init(void)
{

  hsai_BlockA1.Instance = SAI1_Block_A;
  hsai_BlockA1.Init.Protocol = SAI_FREE_PROTOCOL;
  hsai_BlockA1.Init.AudioMode = SAI_MODEMASTER_RX;
  hsai_BlockA1.Init.DataSize = SAI_DATASIZE_24;
  hsai_BlockA1.Init.FirstBit = SAI_FIRSTBIT_MSB;
  hsai_BlockA1.Init.ClockStrobing = SAI_CLOCKSTROBING_RISINGEDGE;
  hsai_BlockA1.Init.Synchro = SAI_ASYNCHRONOUS;
  hsai_BlockA1.Init.OutputDrive = SAI_OUTPUTDRIVE_ENABLE;
  hsai_BlockA1.Init.NoDivider = SAI_MASTERDIVIDER_ENABLE;
  hsai_BlockA1.Init.FIFOThreshold = SAI_FIFOTHRESHOLD_EMPTY;
  hsai_BlockA1.Init.AudioFrequency = SAI_AUDIO_FREQUENCY_48K;
  hsai_BlockA1.Init.SynchroExt = SAI_SYNCEXT_DISABLE;
  hsai_BlockA1.Init.MonoStereoMode = SAI_STEREOMODE;
  hsai_BlockA1.Init.CompandingMode = SAI_NOCOMPANDING;
  hsai_BlockA1.Init.PdmInit.Activation = DISABLE;
  hsai_BlockA1.Init.PdmInit.MicPairsNbr = 1;
  hsai_BlockA1.Init.PdmInit.ClockEnable = SAI_PDM_CLOCK1_ENABLE;
  hsai_BlockA1.FrameInit.FrameLength = 256;
  hsai_BlockA1.FrameInit.ActiveFrameLength = 128;
  hsai_BlockA1.FrameInit.FSDefinition = SAI_FS_CHANNEL_IDENTIFICATION;
  hsai_BlockA1.FrameInit.FSPolarity = SAI_FS_ACTIVE_HIGH;
  hsai_BlockA1.FrameInit.FSOffset = SAI_FS_BEFOREFIRSTBIT;
  hsai_BlockA1.SlotInit.FirstBitOffset = 0;
  hsai_BlockA1.SlotInit.SlotSize = SAI_SLOTSIZE_32B;
  hsai_BlockA1.SlotInit.SlotNumber = 8;
  hsai_BlockA1.SlotInit.SlotActive = 0x0000FFFF;
  if (HAL_SAI_Init(&hsai_BlockA1) != HAL_OK)
  {
    Error_Handler();
  }
  hsai_BlockB1.Instance = SAI1_Block_B;
  hsai_BlockB1.Init.Protocol = SAI_FREE_PROTOCOL;
  hsai_BlockB1.Init.AudioMode = SAI_MODESLAVE_TX;
  hsai_BlockB1.Init.DataSize = SAI_DATASIZE_24;
  hsai_BlockB1.Init.FirstBit = SAI_FIRSTBIT_MSB;
  hsai_BlockB1.Init.ClockStrobing = SAI_CLOCKSTROBING_FALLINGEDGE;
  hsai_BlockB1.Init.Synchro = SAI_SYNCHRONOUS;
  hsai_BlockB1.Init.OutputDrive = SAI_OUTPUTDRIVE_ENABLE;
  hsai_BlockB1.Init.FIFOThreshold = SAI_FIFOTHRESHOLD_EMPTY;
  hsai_BlockB1.Init.SynchroExt = SAI_SYNCEXT_DISABLE;
  hsai_BlockB1.Init.MonoStereoMode = SAI_STEREOMODE;
  hsai_BlockB1.Init.CompandingMode = SAI_NOCOMPANDING;
  hsai_BlockB1.Init.TriState = SAI_OUTPUT_NOTRELEASED;
  hsai_BlockB1.Init.PdmInit.Activation = DISABLE;
  hsai_BlockB1.Init.PdmInit.MicPairsNbr = 1;
  hsai_BlockB1.Init.PdmInit.ClockEnable = SAI_PDM_CLOCK1_ENABLE;
  hsai_BlockB1.FrameInit.FrameLength = 256;
  hsai_BlockB1.FrameInit.ActiveFrameLength = 128;
  hsai_BlockB1.FrameInit.FSDefinition = SAI_FS_CHANNEL_IDENTIFICATION;
  hsai_BlockB1.FrameInit.FSPolarity = SAI_FS_ACTIVE_HIGH;
  hsai_BlockB1.FrameInit.FSOffset = SAI_FS_BEFOREFIRSTBIT;
  hsai_BlockB1.SlotInit.FirstBitOffset = 0;
  hsai_BlockB1.SlotInit.SlotSize = SAI_SLOTSIZE_32B;
  hsai_BlockB1.SlotInit.SlotNumber = 8;
  hsai_BlockB1.SlotInit.SlotActive = 0x0000FFFF;
  if (HAL_SAI_Init(&hsai_BlockB1) != HAL_OK)
  {
    Error_Handler();
  }

}

static void MX_SPI2_Init(void)
{

  /* SPI2 parameter configuration*/
  hspi2.Instance = SPI2;
  hspi2.Init.Mode = SPI_MODE_MASTER;
  hspi2.Init.Direction = SPI_DIRECTION_2LINES;
  hspi2.Init.DataSize = SPI_DATASIZE_8BIT;
  hspi2.Init.CLKPolarity = SPI_POLARITY_HIGH;
  hspi2.Init.CLKPhase = SPI_PHASE_2EDGE;
  hspi2.Init.NSS = SPI_NSS_SOFT;
  hspi2.Init.BaudRatePrescaler = SPI_BAUDRATEPRESCALER_256;
  hspi2.Init.FirstBit = SPI_FIRSTBIT_MSB;
  hspi2.Init.TIMode = SPI_TIMODE_DISABLE;
  hspi2.Init.CRCCalculation = SPI_CRCCALCULATION_DISABLE;
  hspi2.Init.CRCPolynomial = 0x0;
  hspi2.Init.NSSPMode = SPI_NSS_PULSE_DISABLE;
  hspi2.Init.NSSPolarity = SPI_NSS_POLARITY_LOW;
  hspi2.Init.FifoThreshold = SPI_FIFO_THRESHOLD_01DATA;
  hspi2.Init.TxCRCInitializationPattern = SPI_CRC_INITIALIZATION_ALL_ZERO_PATTERN;
  hspi2.Init.RxCRCInitializationPattern = SPI_CRC_INITIALIZATION_ALL_ZERO_PATTERN;
  hspi2.Init.MasterSSIdleness = SPI_MASTER_SS_IDLENESS_00CYCLE;
  hspi2.Init.MasterInterDataIdleness = SPI_MASTER_INTERDATA_IDLENESS_00CYCLE;
  hspi2.Init.MasterReceiverAutoSusp = SPI_MASTER_RX_AUTOSUSP_DISABLE;
  hspi2.Init.MasterKeepIOState = SPI_MASTER_KEEP_IO_STATE_DISABLE;
  hspi2.Init.IOSwap = SPI_IO_SWAP_DISABLE;
  if (HAL_SPI_Init(&hspi2) != HAL_OK)
  {
    Error_Handler();
  }

}

static void MX_UART7_Init(void)
{

  huart7.Instance = UART7;
  huart7.Init.BaudRate = 31250;
  huart7.Init.WordLength = UART_WORDLENGTH_8B;
  huart7.Init.StopBits = UART_STOPBITS_1;
  huart7.Init.Parity = UART_PARITY_NONE;
  huart7.Init.Mode = UART_MODE_TX_RX;
  huart7.Init.HwFlowCtl = UART_HWCONTROL_NONE;
  huart7.Init.OverSampling = UART_OVERSAMPLING_16;
  huart7.Init.OneBitSampling = UART_ONE_BIT_SAMPLE_DISABLE;
  huart7.Init.ClockPrescaler = UART_PRESCALER_DIV1;
  huart7.AdvancedInit.AdvFeatureInit = UART_ADVFEATURE_RXOVERRUNDISABLE_INIT|UART_ADVFEATURE_DMADISABLEONERROR_INIT;
  huart7.AdvancedInit.OverrunDisable = UART_ADVFEATURE_OVERRUN_DISABLE;
  huart7.AdvancedInit.DMADisableonRxError = UART_ADVFEATURE_DMA_DISABLEONRXERROR;
  if (HAL_UART_Init(&huart7) != HAL_OK)
  {
    Error_Handler();
  }
  if (HAL_UARTEx_SetTxFifoThreshold(&huart7, UART_TXFIFO_THRESHOLD_1_8) != HAL_OK)
  {
    Error_Handler();
  }
  if (HAL_UARTEx_SetRxFifoThreshold(&huart7, UART_RXFIFO_THRESHOLD_1_8) != HAL_OK)
  {
    Error_Handler();
  }
  if (HAL_UARTEx_DisableFifoMode(&huart7) != HAL_OK)
  {
    Error_Handler();
  }

}

static void MX_DMA_Init(void)
{

  /* DMA controller clock enable */
  __HAL_RCC_DMA1_CLK_ENABLE();

  /* DMA interrupt init */
  /* DMA1_Stream0_IRQn interrupt configuration */
  HAL_NVIC_SetPriority(DMA1_Stream0_IRQn, 5, 0);
  HAL_NVIC_EnableIRQ(DMA1_Stream0_IRQn);
  /* DMA1_Stream1_IRQn interrupt configuration */
  HAL_NVIC_SetPriority(DMA1_Stream1_IRQn, 5, 0);
  HAL_NVIC_EnableIRQ(DMA1_Stream1_IRQn);
  /* DMA1_Stream2_IRQn interrupt configuration */
  HAL_NVIC_SetPriority(DMA1_Stream2_IRQn, 5, 0);
  HAL_NVIC_EnableIRQ(DMA1_Stream2_IRQn);
  /* DMA1_Stream3_IRQn interrupt configuration */
  HAL_NVIC_SetPriority(DMA1_Stream3_IRQn, 5, 0);
  HAL_NVIC_EnableIRQ(DMA1_Stream3_IRQn);
  /* DMA1_Stream4_IRQn interrupt configuration */
  HAL_NVIC_SetPriority(DMA1_Stream4_IRQn, 5, 0);
  HAL_NVIC_EnableIRQ(DMA1_Stream4_IRQn);

}

/* FMC initialization function */
static void MX_FMC_Init(void)
{

  FMC_SDRAM_TimingTypeDef SdramTiming = {0};

  /** Perform the SDRAM1 memory initialization sequence
  */
  hsdram1.Instance = FMC_SDRAM_DEVICE;
  /* hsdram1.Init */
  hsdram1.Init.SDBank = FMC_SDRAM_BANK1;
  hsdram1.Init.ColumnBitsNumber = FMC_SDRAM_COLUMN_BITS_NUM_9;
  hsdram1.Init.RowBitsNumber = FMC_SDRAM_ROW_BITS_NUM_13;
  hsdram1.Init.MemoryDataWidth = FMC_SDRAM_MEM_BUS_WIDTH_32;
  hsdram1.Init.InternalBankNumber = FMC_SDRAM_INTERN_BANKS_NUM_4;
  hsdram1.Init.CASLatency = FMC_SDRAM_CAS_LATENCY_3;
  hsdram1.Init.WriteProtection = FMC_SDRAM_WRITE_PROTECTION_DISABLE;
  hsdram1.Init.SDClockPeriod = FMC_SDRAM_CLOCK_PERIOD_2;
  hsdram1.Init.ReadBurst = FMC_SDRAM_RBURST_ENABLE;
  hsdram1.Init.ReadPipeDelay = FMC_SDRAM_RPIPE_DELAY_0;
  /* SdramTiming */
  SdramTiming.LoadToActiveDelay = 2;
  SdramTiming.ExitSelfRefreshDelay = 7;
  SdramTiming.SelfRefreshTime = 4;
  SdramTiming.RowCycleDelay = 8;
  SdramTiming.WriteRecoveryTime = 3;
  SdramTiming.RPDelay = 1;
  SdramTiming.RCDDelay = 10;

  if (HAL_SDRAM_Init(&hsdram1, &SdramTiming) != HAL_OK)
  {
    Error_Handler( );
  }

}

static void MX_GPIO_Init(void)
{
  GPIO_InitTypeDef GPIO_InitStruct = {0};

  /* GPIO Ports Clock Enable */
  __HAL_RCC_GPIOE_CLK_ENABLE();
  __HAL_RCC_GPIOB_CLK_ENABLE();
  __HAL_RCC_GPIOG_CLK_ENABLE();
  __HAL_RCC_GPIOD_CLK_ENABLE();
  __HAL_RCC_GPIOC_CLK_ENABLE();
  __HAL_RCC_GPIOA_CLK_ENABLE();
  __HAL_RCC_GPIOI_CLK_ENABLE();
  __HAL_RCC_GPIOH_CLK_ENABLE();
  __HAL_RCC_GPIOF_CLK_ENABLE();

  /*Configure GPIO pin Output Level */
  HAL_GPIO_WritePin(GPIOG, BUT_A_LED_Pin|BUT_B_LED_Pin|ADC_RST_Pin, GPIO_PIN_RESET);

  /*Configure GPIO pin Output Level */
  HAL_GPIO_WritePin(GPIOC, GPIO_PIN_13, GPIO_PIN_RESET);

  /*Configure GPIO pin Output Level */
  HAL_GPIO_WritePin(GPIOH, GPIO_PIN_4, GPIO_PIN_RESET);

  /*Configure GPIO pin Output Level */
  HAL_GPIO_WritePin(GPIOA, GPIO_PIN_0, GPIO_PIN_RESET);

  /*Configure GPIO pin Output Level */
  HAL_GPIO_WritePin(ADC_SPI_NCS_GPIO_Port, ADC_SPI_NCS_Pin, GPIO_PIN_RESET);

  /*Configure GPIO pins : PB8 PB5 PB4 PB9
                           PB6 PB2 PB12 PB13 */
  GPIO_InitStruct.Pin = GPIO_PIN_8|GPIO_PIN_5|GPIO_PIN_4|GPIO_PIN_9
                          |GPIO_PIN_6|GPIO_PIN_2|GPIO_PIN_12|GPIO_PIN_13;
  GPIO_InitStruct.Mode = GPIO_MODE_ANALOG;
  GPIO_InitStruct.Pull = GPIO_NOPULL;
  HAL_GPIO_Init(GPIOB, &GPIO_InitStruct);

  /*Configure GPIO pins : PG14 PG13 PG9 */
  GPIO_InitStruct.Pin = GPIO_PIN_14|GPIO_PIN_13|GPIO_PIN_9;
  GPIO_InitStruct.Mode = GPIO_MODE_ANALOG;
  GPIO_InitStruct.Pull = GPIO_NOPULL;
  HAL_GPIO_Init(GPIOG, &GPIO_InitStruct);

  /*Configure GPIO pins : PD7 PD6 PD5 PD4
                           PD3 PD13 PD12 PD11 */
  GPIO_InitStruct.Pin = GPIO_PIN_7|GPIO_PIN_6|GPIO_PIN_5|GPIO_PIN_4
                          |GPIO_PIN_3|GPIO_PIN_13|GPIO_PIN_12|GPIO_PIN_11;
  GPIO_InitStruct.Mode = GPIO_MODE_ANALOG;
  GPIO_InitStruct.Pull = GPIO_NOPULL;
  HAL_GPIO_Init(GPIOD, &GPIO_InitStruct);

  /*Configure GPIO pins : PA15 PA10 PA1 PA4
                           PA5 PA3 PA7 */
  GPIO_InitStruct.Pin = GPIO_PIN_15|GPIO_PIN_10|GPIO_PIN_1|GPIO_PIN_4
                          |GPIO_PIN_5|GPIO_PIN_3|GPIO_PIN_7;
  GPIO_InitStruct.Mode = GPIO_MODE_ANALOG;
  GPIO_InitStruct.Pull = GPIO_NOPULL;
  HAL_GPIO_Init(GPIOA, &GPIO_InitStruct);

  /*Configure GPIO pin : PB7 */
  GPIO_InitStruct.Pin = GPIO_PIN_7;
  GPIO_InitStruct.Mode = GPIO_MODE_AF_OD;
  GPIO_InitStruct.Pull = GPIO_NOPULL;
  GPIO_InitStruct.Speed = GPIO_SPEED_FREQ_LOW;
  GPIO_InitStruct.Alternate = GPIO_AF4_I2C1;
  HAL_GPIO_Init(GPIOB, &GPIO_InitStruct);

  /*Configure GPIO pins : BUT_A_LED_Pin BUT_B_LED_Pin ADC_RST_Pin */
  GPIO_InitStruct.Pin = BUT_A_LED_Pin|BUT_B_LED_Pin|ADC_RST_Pin;
  GPIO_InitStruct.Mode = GPIO_MODE_OUTPUT_PP;
  GPIO_InitStruct.Pull = GPIO_NOPULL;
  GPIO_InitStruct.Speed = GPIO_SPEED_FREQ_LOW;
  HAL_GPIO_Init(GPIOG, &GPIO_InitStruct);

  /*Configure GPIO pin : BUT_B_Pin */
  GPIO_InitStruct.Pin = BUT_B_Pin;
  GPIO_InitStruct.Mode = GPIO_MODE_IT_RISING;
  GPIO_InitStruct.Pull = GPIO_PULLUP;
  HAL_GPIO_Init(BUT_B_GPIO_Port, &GPIO_InitStruct);

  /*Configure GPIO pins : PC11 PC14 PC8 PC7
                           PC6 */
  GPIO_InitStruct.Pin = GPIO_PIN_11|GPIO_PIN_14|GPIO_PIN_8|GPIO_PIN_7
                          |GPIO_PIN_6;
  GPIO_InitStruct.Mode = GPIO_MODE_ANALOG;
  GPIO_InitStruct.Pull = GPIO_NOPULL;
  HAL_GPIO_Init(GPIOC, &GPIO_InitStruct);

  /*Configure GPIO pin : PC13 */
  GPIO_InitStruct.Pin = GPIO_PIN_13;
  GPIO_InitStruct.Mode = GPIO_MODE_OUTPUT_PP;
  GPIO_InitStruct.Pull = GPIO_NOPULL;
  GPIO_InitStruct.Speed = GPIO_SPEED_FREQ_LOW;
  HAL_GPIO_Init(GPIOC, &GPIO_InitStruct);

  /*Configure GPIO pins : PI8 PI11 */
  GPIO_InitStruct.Pin = GPIO_PIN_8|GPIO_PIN_11;
  GPIO_InitStruct.Mode = GPIO_MODE_ANALOG;
  GPIO_InitStruct.Pull = GPIO_NOPULL;
  HAL_GPIO_Init(GPIOI, &GPIO_InitStruct);

  /*Configure GPIO pin : BUT_A_Pin */
  GPIO_InitStruct.Pin = BUT_A_Pin;
  GPIO_InitStruct.Mode = GPIO_MODE_IT_RISING;
  GPIO_InitStruct.Pull = GPIO_PULLUP;
  HAL_GPIO_Init(BUT_A_GPIO_Port, &GPIO_InitStruct);

  /*Configure GPIO pin : PC15 */
  GPIO_InitStruct.Pin = GPIO_PIN_15;
  GPIO_InitStruct.Mode = GPIO_MODE_INPUT;
  GPIO_InitStruct.Pull = GPIO_NOPULL;
  HAL_GPIO_Init(GPIOC, &GPIO_InitStruct);

  /*Configure GPIO pin : PC9 */
  GPIO_InitStruct.Pin = GPIO_PIN_9;
  GPIO_InitStruct.Mode = GPIO_MODE_IT_RISING;
  GPIO_InitStruct.Pull = GPIO_NOPULL;
  HAL_GPIO_Init(GPIOC, &GPIO_InitStruct);

  /*Configure GPIO pin : PH4 */
  GPIO_InitStruct.Pin = GPIO_PIN_4;
  GPIO_InitStruct.Mode = GPIO_MODE_OUTPUT_PP;
  GPIO_InitStruct.Pull = GPIO_NOPULL;
  GPIO_InitStruct.Speed = GPIO_SPEED_FREQ_LOW;
  HAL_GPIO_Init(GPIOH, &GPIO_InitStruct);

  /*Configure GPIO pins : PH6 PH7 */
  GPIO_InitStruct.Pin = GPIO_PIN_6|GPIO_PIN_7;
  GPIO_InitStruct.Mode = GPIO_MODE_ANALOG;
  GPIO_InitStruct.Pull = GPIO_NOPULL;
  HAL_GPIO_Init(GPIOH, &GPIO_InitStruct);

  /*Configure GPIO pin : PA0 */
  GPIO_InitStruct.Pin = GPIO_PIN_0;
  GPIO_InitStruct.Mode = GPIO_MODE_OUTPUT_PP;
  GPIO_InitStruct.Pull = GPIO_NOPULL;
  GPIO_InitStruct.Speed = GPIO_SPEED_FREQ_LOW;
  HAL_GPIO_Init(GPIOA, &GPIO_InitStruct);

  /*Configure GPIO pin : ADC_SPI_NCS_Pin */
  GPIO_InitStruct.Pin = ADC_SPI_NCS_Pin;
  GPIO_InitStruct.Mode = GPIO_MODE_OUTPUT_PP;
  GPIO_InitStruct.Pull = GPIO_NOPULL;
  GPIO_InitStruct.Speed = GPIO_SPEED_FREQ_LOW;
  HAL_GPIO_Init(ADC_SPI_NCS_GPIO_Port, &GPIO_InitStruct);

  /* EXTI interrupt init*/
  HAL_NVIC_SetPriority(EXTI2_IRQn, 5, 0);
  HAL_NVIC_EnableIRQ(EXTI2_IRQn);

  HAL_NVIC_SetPriority(EXTI15_10_IRQn, 5, 0);
  HAL_NVIC_EnableIRQ(EXTI15_10_IRQn);

}

/* USER CODE BEGIN Header_StartDefaultTask */
#if 0
/**
  * @brief  Function implementing the defaultTask thread.
  * @param  argument: Not used
  * @retval None
  */
/* USER CODE END Header_StartDefaultTask */
void StartDefaultTask(void const * argument)
{
  /* init code for USB_DEVICE */
  MX_USB_DEVICE_Init();

  /* init code for USB_HOST */
  MX_USB_HOST_Init();
  /* USER CODE BEGIN 5 */
#endif
  void StartDefaultTask(void const * argument) {
  /* init code for USB_DEVICE */
  /* NOTE: we get frequent boot failures if host is called first */
  MX_USB_DEVICE_Init();

#ifdef USE_USB_HOST
  /* init code for USB_HOST */
  MX_USB_HOST_Init();
#endif

  setup();

  /* Infinite loop */
  for(;;)
  {
    loop();
  }
  /* USER CODE END 5 */
}

void Error_Handler(void)
{
  /* USER CODE BEGIN Error_Handler_Debug */
#ifdef DEBUG
  __asm__("BKPT");
#else
  NVIC_SystemReset();
#endif
  /* USER CODE END Error_Handler_Debug */
}

#ifdef  USE_FULL_ASSERT
/**
  * @brief  Reports the name of the source file and the source line number
  *         where the assert_param error has occurred.
  * @param  file: pointer to the source file name
  * @param  line: assert_param error line source number
  * @retval None
  */
void assert_failed(uint8_t *file, uint32_t line)
{
  /* USER CODE BEGIN 6 */
#ifdef DEBUG
  __asm__("BKPT");
#else
  NVIC_SystemReset();
#endif
  /* USER CODE END 6 */
}
#endif /* USE_FULL_ASSERT */

/************************ (C) COPYRIGHT STMicroelectronics *****END OF FILE****/
